# RL6678_IP_SVD register map
Vendor: Realtek
Registers are 32-bit, read-write, reset 0x0 unless marked. A register's access mark holds for its fields unless they carry their own. Offsets are from the block's base; [hi:lo] are bit positions; {n}, {i} and the like mark numbered series.

## TIMER8_REG
Base 0x4100A000
Same registers: TIMER9_REG 0x4100A200, TIMER10_REG 0x4100A400, TIMER11_REG 0x4100A600, TIMER12_REG 0x4100A800, TIMER13_REG 0x4100AA00, TIMER{n}_REG {0x4200B000+0x200*n} (n=0..7)
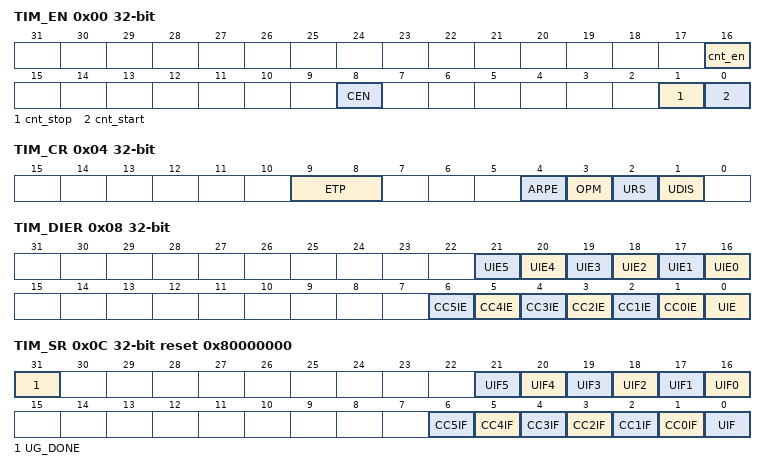
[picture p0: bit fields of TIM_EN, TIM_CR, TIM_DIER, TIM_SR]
0x00 TIM_EN access per field — TIM enable register
  [16] cnt_en ro — Counter working status * 0: counter is stoppped * 1: counter is working
  [8] CEN ro — Counter run status * 0: counter is disabled * 1: counter is enabled
  [1] cnt_stop wo — Disable the counter. Poll cnt_run to see the counter status. If cnt_run is 0, it means that the counter has been disabled internally.
  [0] cnt_start wo — Enable the counter. Poll cnt_run to see the counter status. If cnt_run is 1, it means that the counter has been enabled internally.
0x04 TIM_CR — TIM control register
  [9:8] ETP — External trigger polarity (TRGI) * 0: positive edge is active * 1: negative edge is active * 2 or 3: both edge is active Note: these bits are only valid in one-pulse mode.
  [4] ARPE — Enable auto-reload preloading * 0: TIM_ARR register is not buffered * 1: TIM_ARR register is buffered
  [3] OPM — One-pulse mode * 0: counter is not stopped at UEV * 1: counter stops counting at next UEV
  [2] URS — update request source * 0: counter overflow and setting the UG bit * 1: counter overflow
  [1] UDIS — Disable uev. Shadow registers keep their values. Otherwise, buffered registers are then loaded with their preload values when uev happens.
0x08 TIM_DIER — TIM interupt enable register
  [n+16] UIE{n} (n=0..5) — Enable channel {n} update interrupt
  [n+1] CC{n}IE (n=0..5) — Enable capture/compare {n} interrupt
  [0] UIE — Enable counter update interrupt
0x0C TIM_SR access per field reset 0x80000000 — TIM status register
  [31] UG_DONE ro — UG operation status.This bit is cleared by hardware when the ug bit in the timx_egr register is set. When the ug operation is done, hardware set this bit to '1'. So, software can poll this bit to see the ug operation status.
  [n+16] UIF{n} rw (n=1..5) — Refer to uif0 description
  [16] UIF0 rw — Update interrupt flag of channel0.this flag is set by hardware when the uie0 bit in the timx_egr register is set, and update interrupt of channel 0 happens.
  [n+1] CC{n}IF rw (n=1..5) — Refer to cc0if description
  [1] CC0IF rw — Capture/compare 0 interrupt flag. Channel cc0 configured as output,this flag is set by hardware when the counter tim_cnt value matches the value of tim_ccr0 register. It is cleared by software. Channel cc0 configured as input,this flag is set by hardware and the counter value has been captured in ccr0 field of tim_ccr0 register when an active edge has been detected. It is cleared by software.
  [0] UIF rw — Update interrupt flag
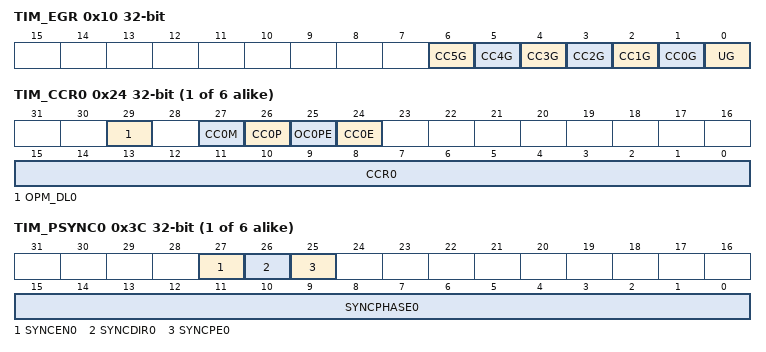
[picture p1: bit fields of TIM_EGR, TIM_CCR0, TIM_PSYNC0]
0x10 TIM_EGR wo — TIM event generation register
  [n+1] CC{n}G (n=1..5) — Refer to cc0g description
  [1] CC0G — Capture/compare 0 generation.this bit is set by software and is automatically cleared by hardware. Channel cc0 configured as output,the cc0if flag is set, the corresponding interrupt or request is sent if enabled. Channel cc0 configured as input,the current value of counter is capture in ccr0 field of tim_ccr0 register. The cc0if flag is set, the corresponding interrupt or request is sent if enabled.
  [0] UG — Update generation. Re-initialize the counter and generate an update of registers. Note that the prescaler counter is cleared too (anyway the prescaler ratio is not affected).
0x14 TIM_CNT ro — TIM counter
  [15:0] CNT — Counter value
0x18 TIM_PSC — TIM prescaler register
  [15:0] PSC — Prescaler value. Psc contains the value to be loaded in the actual prescaler register at each uev (including when the counter is cleared through ug bit of tim_egr register).
0x1C TIM_ARR reset 0xFFFF — TIM auto-reload register
  [15:0] ARR — The value to be loaded in the actual auto-reload register. It can be preloaded by setting arpe bit in tim_cr.
{0x24+4i} TIM_CCR{i} (i=0..5) — TIM Capture/Compare register {i}
  [29] OPM_DL{i} — One Pulse Mode default level 0: default level is 0 1: default level is 1 This bit takes effect only in PWM output mode's One-Pulse-Mode.
  [27] CC{i}M — CC{i} working mode * 0: PWM mode * 1: Input capture mode
  [26] CC{i}P — CC{i} channel configured as output: * 0: OC{i} active high * 1: OC{i} ative low CC{i} channel configured as input: * 0: positive edge of TRGI is active for capture * 1: negative edge of TRGI is active for capture
  [25] OC{i}PE — Enable output capture {i} preload * 0: disable preload register on CCR{i}. CCR{i} can be written at any time, the new value is taken into account immediately. * 1: enable preload register on CCR{i}. Read/Write operations access the preload register. CCR{i} preload value is loaded in the active register at each UEV.
  [24] CC{i}E — Enable CC{i}
  [15:0] CCR{i} — Capture/Compare {i} value CC{i} channel configured as output: CCR{i} is the value to be loaded in the actual capture/compare {i} register (preload value). It is loaded permanently if the preload feature is not selected in the OC{i}PE bit. Else the preload value is copied in the active capture/compare {i} register when an UEV occurs. The active capture/compare {i} register contains the value to be compared to the counter TIM_CNT and signalled on OC{i} output. CC{i} channel configured as pulse mode 1: CCR{i} is the counter value transferred by the last input capture event (TRGI)
{0x3C+4i} TIM_PSYNC{i} (i=0..5) — TIM Phase Synchronization register {i}
  [27] SYNCEN{i} — Enable phase sync function in channel {i}. Phase sync takes effect only in output PWM mode.
  [26] SYNCDIR{i} — Phase sync direction to the reference counter: 0: delay to the reference counter 1: ahead to the reference counter
  [25] SYNCPE{i} — Enable sync phase parameter preload * 0: disable preload register on PSYNC{i}. PSYNC{i} can be written at any time, the new value is taken into account immediately. * 1: enable preload register on PSYNC{i}. Read/Write operations access the preload register. PSYNC{i} preload value is loaded in the active register at each UEV.
  [15:0] SYNCPHASE{i} — The deviation value of channel{i} to the reference counter
{0x54+4i} TIM_PHASECNT{i} ro (i=0..5) — TIM phase counter register {i}
  [15:0] CNT{i} — Phase counter value of channel{i}
